# Global_Reg_CM register map
Vendor: Texas Instruments
Peripheral module from a debugger description file (folder omap34xx).
Registers are 32-bit, access per field, reset 0x0 unless marked. A register's access mark holds for its fields unless they carry their own. Offsets are as the file gives them; lines under a group give offsets from that group; [hi:lo] are bit positions; {n}, {i} and the like mark numbered series; 'fields as' and 'values as' point back to an identical list; <NAME> marks a mode.

## Global_Reg_CM
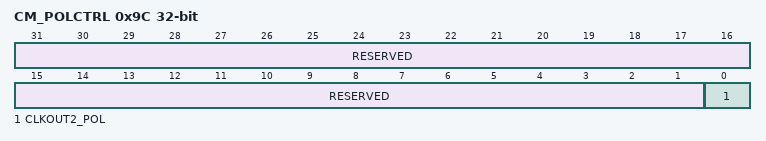
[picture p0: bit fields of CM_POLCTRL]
0x9C CM_POLCTRL — This register allows setting the polarity of device outputs control signals.
  [31:1] RESERVED ro — Write 0s for future compatibility. Read returns 0.
  [0] CLKOUT2_POL rw — Controls the external output clock 2 polarity when disabled
    0=sys_clkout2 is gated low when inactive; 1=sys_clkout2 is gated high when inactive
